# cslr_psc_001 register map
Vendor: Texas Instruments
Peripheral module from a debugger description file.
Registers are 32-bit, read-only, reset values left out (the file's numbers can be read two ways) unless marked. A register's access mark holds for its fields unless they carry their own. Offsets are as the file gives them; lines under a group give offsets from that group; [hi:lo] are bit positions; {n}, {i} and the like mark numbered series; 'fields as' and 'values as' point back to an identical list; <NAME> marks a mode.

## PSC — Power and Sleep Controller (PSC)
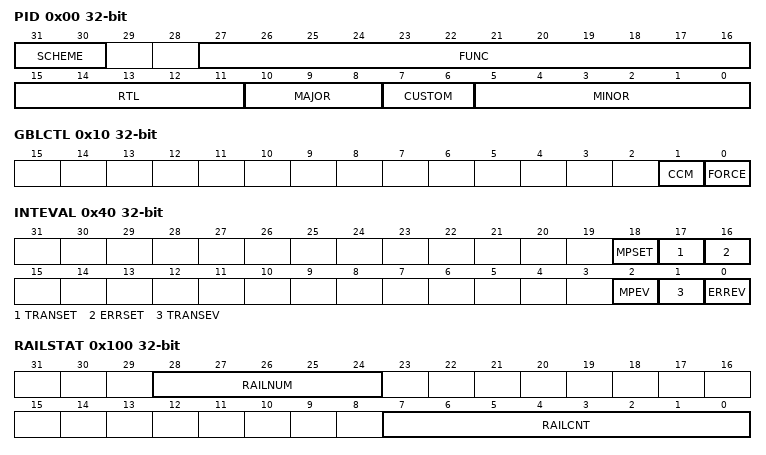
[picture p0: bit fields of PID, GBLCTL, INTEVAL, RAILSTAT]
0x00 PID — Peripheral Revision and Class Information
  [31:30] SCHEME — Used to distinguish between old scheme and current. Spare bit to encode future schemes
  [27:16] FUNC — Indicating a software compatible module family. If there is no level of software compatibility a new ID should be assigned.
  [15:11] RTL — RTL Version. (R as described in PDR 9.3.2) Must be easily ECO'able or controlled during fabrication. Ideally through a top level metal mask or efuse. Start with 0 for PSC1.0, 1 for PSC2.0
  [10:8] MAJOR — Major Revision.
  [7:6] CUSTOM — Indicates a Special Version for a particular device. Consequence of use may avoid use of standard CSL/Drivers. 0 if non-custom
  [5:0] MINOR — Minor Revision Must be easily ECO'able or controlled during fabrication. Ideally through a top level metal mask or efuse. Start with 0.
0x10 GBLCTL access per field — Global Control Register
  [1] CCM rw — PSC MMR controlled by Chip Config Module (CCM) only 0: Software is allowed to control PSC 1: PSC is controlled by CCM
  [0] FORCE rw — Force bit. For PSC 2.0, this bit is considered only if all of the conditions are true: -GBLCTL.CCM = 0 -Software manual control method is used 0: No force 1: Force
0x14 GBLSTAT — Global Status Register
  [0] GBLTRANS — PSC Global Transition Status 0: No Global Transition in progress 1: Global Transition in progress. PSC hardware is in the process of putting all power domains to the desired next states, and all modules to the desired next states
0x20 ERRPR0 — Error Pending 0 (mod 0 - 31) Register
  [31:0] M_32 — Records pending error conditions for modules 0-31. Each bit n respresents a module. For each bit n, 0: Module n does not have error condition 1: Module n has error condition
0x24 ERRPR1 — Error Pending 1 (mod 32 - 63) Register
  [31:0] M_32 — Records pending error conditions for modules 32-63. Each bit n respresents a module. For each bit n, 0: Module n does not have error condition 1: Module n has error condition
0x30 ERRCR0 wo — Error Clear 0 (mod 0-31) Register
  [31:0] M_32 — Clears error bit set in corresponding ERRPR register bit field. This pertains to modules 0-31. For each bit n, 0: Write of 0 has no effect 1: Write of 1 to bit n causes ERRPR bit n to be cleared, and the corresponding module's MDSTAT fields to be cleared - STERR, WKRSLP, ACSLP, MSTID.
0x34 ERRCR1 wo — Error Clear 1 (mod 32-63) Register
  [31:0] M_32 — Clears error bit set in corresponding ERRPR register bit field. This pertains to modules 32-63. For each bit n, 0: Write of 0 has no effect 1: Write of 1 to bit n causes ERRPR bit n to be cleared, and the corresponding module's MDSTAT fields to be cleared - STERR, WKRSLP, ACSLP, MSTID.
0x40 INTEVAL access per field — Interrupt Evaluation Register
  [18] MPSET wo — Memory Protection Interrupt Set (not documented to users) 0: Write of 0 has no effect 1: Write of 1 causes the PSC_MPINT to be pulsed
  [17] TRANSET wo — State Transition Interrupt Set (not documented to users) 0: Write of 0 has no effect 1: Write of 1 causes the PSC_TRANSINT to be pulsed
  [16] ERRSET wo — Error Interrupt Set (not documented to users) 0: Write of 0 has no effect 1: Write of 1 causes the PSC_ERRINT to be pulsed
  [2] MPEV wo — Re-evaluate Memory Protection Interrupt 0: Write of 0 has no effect 1: Write of 1 re-evaluates memory protection interrupt PSC_MPINT. Write of 1 causes interrupt logic to re-evaluate all pending Memory Protection error conditions and re-pulse the PSC_MPINT if any memory protection error conditions are pending
  [1] TRANSEV wo — Re-evaluate State Transition Interrupt 0: Write of 0 has no effect 1: Write of 1 re-evaluates state transition interrupt PSC_TRANSINT. Write of 1 causes interrupt logic to re-evaluate all pending MTSTAT conditions and re-pulse the PSC_TRANSINT if any MTSTAT bits are still set.
  [0] ERREV wo — Re-evaluate Error Interrupt 0: Write of 0 has no effect 1: Write of 1 re-evaluates error interrupt PSC_ERRINT. Write of 1 causes interrupt logic to re-evaluate all pending error interrupts and re-pulse the error interrupt signal if any error interrupt conditions are pending
0x100 RAILSTAT — Power Rail Status Register
  [28:24] RAILNUM — Indicates Current Rail Requestor being processed by GPSC. Defaults to 0 indicating Always ON domain that has no rail request/grant associated with it. The 5 bit field allows up to 32 requestors.
  [7:0] RAILCNT — Indicates the current rail counter value. This is a dynamic field and reading this will not reflect real-time value.
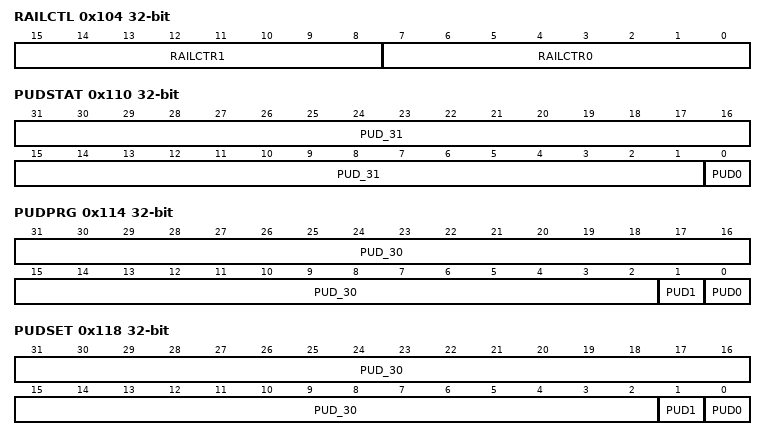
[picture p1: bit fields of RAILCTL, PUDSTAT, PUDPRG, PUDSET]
0x104 RAILCTL access per field — Power Rail Counter Control Register
  [15:8] RAILCTR1 rw — Rail Counter Value 1
  [7:0] RAILCTR0 rw — Rail Counter Value 0
0x108 RAILSEL rw — Power Rail Counter Select Register
  [31:0] P_32 — Rail Counter Select for Power Domain n 0: Use RAILCTL.RailCtr0 count value to bring up power domain n 1: Use RAILCTL.RailCtr1 count value to bring up power domain n
0x110 PUDSTAT — Power Up Domain Status Register
  [31:1] PUD_31 — Indicates Power ON for each power domain after the respective PUD bit is turned ON. This bit should be polled before turning OFF the isolation cells.
  [0] PUD0 — This bit indicates that the power is ON and stable for the Always ON domain. 0: Power not ON (may be in progress) 1: Power for domain is ON PUD0 belongs to the Always ON domain and therefore it defaults to ON (1)
0x114 PUDPRG — Power Up Domain Programmed Register
  [31:2] PUD_30 — Power Up Domain n , where n ranges 31 down-to 2. 0: Power domain n turns OFF 1: Power domain n turns ON
  [1] PUD1 — Power Up Domain 1 0: Power Domain 1 turns OFF 1: Power Domain 1 turns ON
  [0] PUD0 — Always ON Power Domain control bit. This bit is tied off to 1. Modules that need to be powered on along with the device belong in this power domain.
0x118 PUDSET access per field — Power Up Domain Set Register
  [31:2] PUD_30 wo — Power Up Domains n, where n ranges 31 down-to 2. 0: Writes of 0 have no effect 1: Writes of 1 asserts PUDPRG.PUD[n] to initiate power on for domain n
  [1] PUD1 wo — Power Up Domain 1 0: Writes of 0 have no effect 1: Writes of 1 asserts PUDPRG.PUD1 to initiate power on for domain 1
  [0] PUD0 ro — Set PUDPRG bit 0. Note that Power Domain 0 is the Always On power domain, which is always on. Therefore this bit is special and it is not writeable.
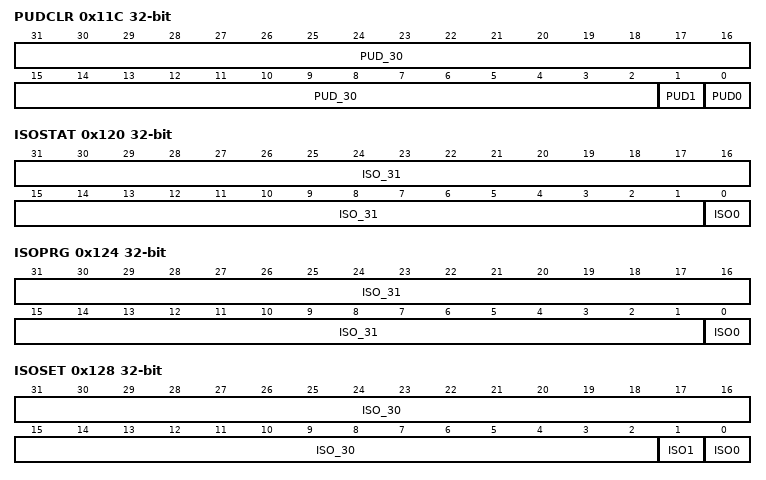
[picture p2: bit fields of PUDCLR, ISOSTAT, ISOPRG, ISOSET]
0x11C PUDCLR access per field — Power Up Domain Clear Register
  [31:2] PUD_30 wo — Power Down Domains n, where n ranges 31 down-to 2. 0: Writes of 0 have no effect 1: Writes of 1 clears PUDPRG.PUD[n] to turn off power for domain n
  [1] PUD1 wo — Power Down Domain 1 0: Writes of 0 have no effect 1: Writes of 1 clears PUDPRG.PUD1 to turn off power for domain 1
  [0] PUD0 ro — Clear PUDPRG bit 0. Note that Power Domain 0 is the Always On power domain, which is always on. Therefore this bit is special and it is not writeable to change the domain state.
0x120 ISOSTAT — Isolation Status Register
  [31:1] ISO_31 — Isolation cell status for power domains 31 down to 1: 0: Power domain is not isolated. 1: Power domain is isolated.
  [0] ISO0 — Always ON Power Domain's Isolation cell status bit. This bit indicates that the domain is not isolated (0).
0x124 ISOPRG — Isolation Cell Programmed Register
  [31:1] ISO_31 — Isolation cell control for power domains 31 down to 1: 0: Isolation cell is OFF. Power domain is not isolated 1: Isolation cell is ON. Power domain is isolated The actual ON or OFF stable state is read from the isolation Cell Status register.
  [0] ISO0 — Always ON Power Domain's Isolation cell control bit. This bit is tied to 0
0x128 ISOSET access per field — Isolation Cell Set Register
  [31:2] ISO_30 wo — Turn on the isolations cells for Power domains 31 down to 2: 0: Writes of 0 have no effect 1: Writes of 1 asserts ISOPRG.ISO[n] to tun on iso. cells for domain n
  [1] ISO1 wo — Turn on the isolations cells for Power domain 1 0: Writes of 0 have no effect 1: Writes of 1 asserts ISOPRG.ISO1 to tun on iso. cells for domain 1
  [0] ISO0 ro — Set ISOPRG bit 0. Note that Power Domain 0 is the Always ON power domain and therefore the isolation cells are always off (0). Therefore this bit is special and it is not writeable.
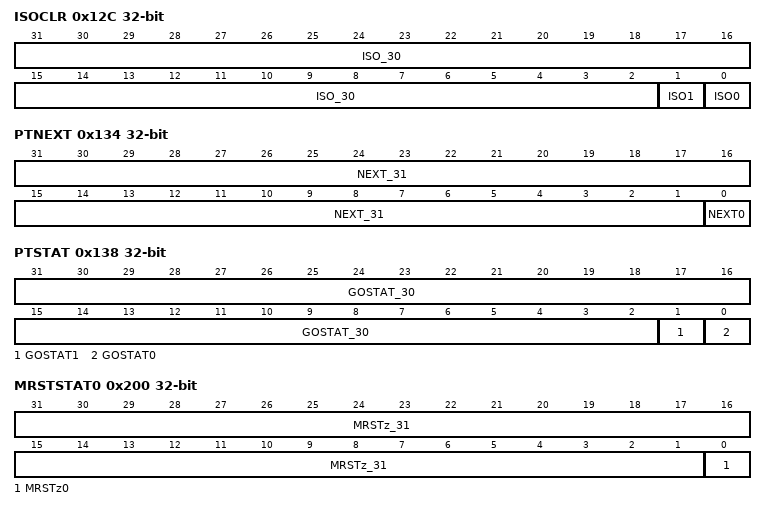
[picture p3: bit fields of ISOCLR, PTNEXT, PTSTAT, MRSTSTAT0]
0x12C ISOCLR access per field — Isolation Cell Clear Register
  [31:2] ISO_30 wo — Clear ISO[n] bit to turn off iso. Cells for Power Domain n , where n ranges from 31 down-to 2. 0: Writes of 0 have no effect 1: Writes of 1 clears ISO[n] to turn off iso cells for domain n
  [1] ISO1 wo — Clear ISO1 bit to turn off iso. Cells for Power Domain 1. 0: Writes of 0 have no effect 1: Writes of 1 clears ISO1 to turn off iso cells for domain 1
  [0] ISO0 ro — Clear ISO0. Note that Power Domain 0 is the Always ON power domain and therefore the isolations cells are always off. Therefore this bit is special and it is not writeable to change the domain state.
0x130 PTCMD rw — Power Domain Transition Command Register
  [31:0] GO_32 — PSC 1.0 definition: Power Domain n Evaluation 0: Writes of 0 has no effect 1: Writes of 1 cause the State Transition Interrupt Generation Block to evaluate the new PTNEXT and MDCTL.NEXT states as the Application desired states. PSC 2.0 definition: Power Domain n GO Transition 0: Writes of 0 have no effect 1: Writes of 1 cause PSC hardware to evaluate PTNEXT and MDCTL.NEXT (for this domain).
0x134 PTNEXT — Power Domain Transition Next State Register
  [31:1] NEXT_31 — Power Domain n Next State 0: OFF(PUD = 0, ISO = 1) 1: ON (PUD = 1, ISO = 0)
  [0] NEXT0 — Power Domain 0 Next State Since power domain 0 is reserved for the Always ON domain, this bit is always 1 to indicate that Power Domain 0's next state is ON.
0x138 PTSTAT — Power Domain Transition Status Register
  [31:2] GOSTAT_30 — Power Domain n Transition Command Status, where n ranges from 31 down to 2 0: No transitions in progress in Power Domain 0 1: Power Domain 0 Transition in progress - either the power domain is transitioning, or modules on this domain are transitioning.
  [1] GOSTAT1 — Power Domain 1 Transition Command Status 0: No transitions in progress in Power Domain 0 1: Power Domain 0 Transition in progress - either the power domain is transitioning, or modules on this domain are transitioning.
  [0] GOSTAT0 — Power Domain 0 Transition Command Status Power domain 0 is reserved for the Always ON domain, this bit is always 0.
0x200 MRSTSTAT0 — Module Reset Status 0 (mod 0 - 31) Register
  [31:1] MRSTz_31 — Shows Module 1 to Module 31's reset status
  [0] MRSTz0 — 0: Module reset is asserted low. 1: Module reset is de-asserted high.
0x204 MRSTSTAT1 — Module Reset Status 1 (mod 32-63) Register
  [31:0] MRSTz_32 — Shows Module 32 to Module 63's reset status
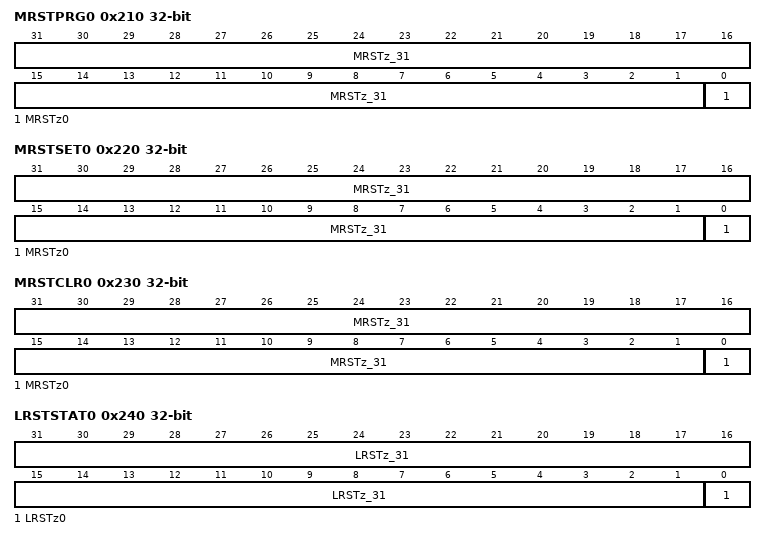
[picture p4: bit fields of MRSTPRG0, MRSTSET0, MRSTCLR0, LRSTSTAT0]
0x210 MRSTPRG0 — Module Reset Programmed 0 (mod 0 - 31) Register
  [31:1] MRSTz_31 — Controls Module 1 to Module 31's reset
  [0] MRSTz0 — 0: Module reset is asserted low. 1: Module reset is de-asserted high.
0x214 MRSTPRG1 — Module Reset Programmed 1 (mod 32 - 63) Register
  [31:0] MRSTz_32 — Controls Module 32 to Module 63's reset
0x220 MRSTSET0 wo — Module Reset Set 0 (mod 0 - 31) Register
  [31:1] MRSTz_31 — For Modules 31 down to 1, 0: Writes of 0 have no effect 1: Writes of 1 set MRSTz[n] to de-assert reset to that module
  [0] MRSTz0 — Set to de-assert module reset 0: Writes of 0 have no effect 1: Writes of 1 set MRSTz0 to de-assert reset to module 0
0x224 MRSTSET1 wo — Module Reset Set 1 (mod 32 - 63) Register
  [31:0] MRSTz_32 — For Modules 63 down to 32, 0: Writes of 0 have no effect 1: Writes of 1 set MRSTz[n] to de-assert reset to that module
0x230 MRSTCLR0 wo — Module Reset Clear 0 (mod 0 - 31) Register
  [31:1] MRSTz_31 — For Modules 31 down to 1, 0: Writes of 0 have no effect 1: Writes of 1 clear MRSTz[n] to assert reset to that module
  [0] MRSTz0 — Clear to assert module reset 0: Writes of 0 have no effect 1: Writes of 1 clear MRSTz0 to assert reset to module 0
0x234 MRSTCLR1 wo — Module Reset Clear 1 (mod 32 - 63) Register
  [31:0] MRSTz_32 — For Modules 63 down to 32, 0: Writes of 0 have no effect 1: Writes of 1 clear MRSTz[n] to assert reset to that module
0x240 LRSTSTAT0 — Module Local Reset Status 0 (mod 0 - 31) Register
  [31:1] LRSTz_31 — Shows Module 1 to Module 31's local reset status
  [0] LRSTz0 — 0: Module local reset is asserted. 1: Module local reset is de-asserted.
0x244 LRSTSTAT1 — Module Local Reset Status 1 (mod 32-63) Register
  [31:0] MRSTz_32 — Shows Module 32 to Module 63's local reset status
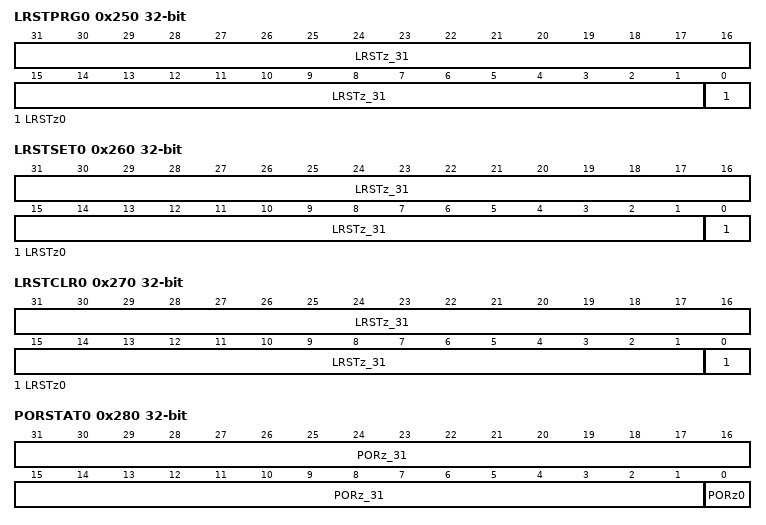
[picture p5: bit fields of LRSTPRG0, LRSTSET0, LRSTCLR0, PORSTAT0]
0x250 LRSTPRG0 — Module Local Reset Programmed 0 (mod 0 - 31) Register
  [31:1] LRSTz_31 — Controls Module 1 to Module 31's local reset
  [0] LRSTz0 — 0: Module local reset is asserted. 1: Module local reset is de-asserted.
0x254 LRSTPRG1 — Module Local Reset Programmed 1 (mod 32 - 63) Register
  [31:0] LRSTz_32 — Controls Module 32 to Module 63's local reset
0x260 LRSTSET0 wo — Module Local Reset Set 0 (mod 0 - 31) Register
  [31:1] LRSTz_31 — For Modules 31 down to 1, 0: Writes of 0 have no effect 1: Writes of 1 set LRSTz[n] to de-assert local reset to that module
  [0] LRSTz0 — Set to de-assert module local reset 0: Writes of 0 have no effect 1: Writes of 1 set LRSTz0 to de-assert local reset to module 0
0x264 LRSTSET1 wo — Module Local Reset Set 1 (mod 32 - 63) Register
  [31:0] LRSTz_32 — For Modules 63 down to 32, 0: Writes of 0 have no effect 1: Writes of 1 set LRSTz[n] to de-assert local reset to that module
0x270 LRSTCLR0 wo — Module Local Reset Clear 0 (mod 0 - 31) Register
  [31:1] LRSTz_31 — For Modules 31 down to 1, 0: Writes of 0 have no effect 1: Writes of 1 clear LRSTz[n] to assert local reset to that module
  [0] LRSTz0 — Clear to assert module local reset 0: Writes of 0 have no effect 1: Writes of 1 clear LRSTz0 to assert local reset to module 0
0x274 LRSTCLR1 wo — Module Local Reset Clear 1 (mod 32 - 63) Register
  [31:0] LRSTz_32 — For Modules 63 down to 32, 0: Writes of 0 have no effect 1: Writes of 1 clear LRSTz[n] to assert local reset to that module
0x280 PORSTAT0 — Module Power On Reset Status 0 (mod 0 - 31) Register
  [31:1] PORz_31 — Shows Module 1 to Module 31's PORz reset status
  [0] PORz0 — 0: Module PORz reset is asserted. 1: Module PORz reset is de-asserted.
0x284 PORSTAT1 — Module Power On Reset Status 1 (mod 32-63) Register
  [31:0] PORz_32 — Shows Module 32 to Module 63's PORz reset status
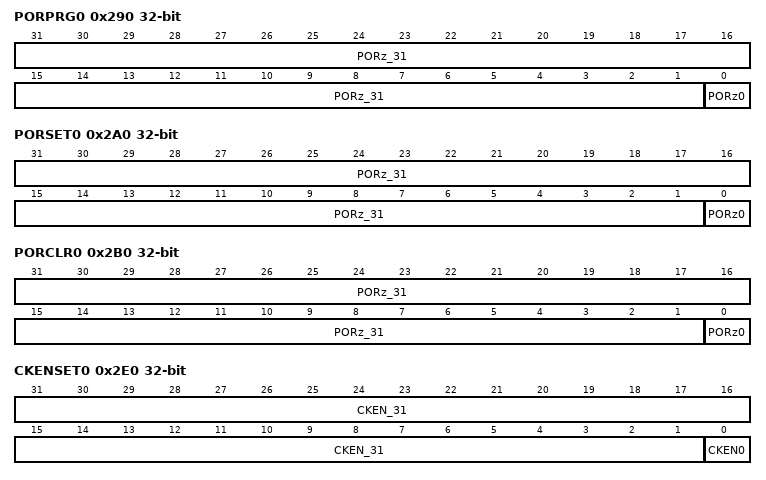
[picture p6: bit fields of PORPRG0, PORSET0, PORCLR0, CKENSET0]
0x290 PORPRG0 — Module Power On Reset Programmed 0 (mod 0 - 31) Register
  [31:1] PORz_31 — Controls Module 1 to Module 31's PORz reset
  [0] PORz0 — 0: Module PORz reset is asserted. 1: Module PORz reset is de-asserted.
0x294 PORPRG1 — Module Power On Reset Programmed 1 (mod 32 - 63) Register
  [31:0] PORz_32 — Controls Module 32 to Module 63's PORz reset
0x2A0 PORSET0 wo — Module Power On Reset Set 0 (mod 0 - 31) Register
  [31:1] PORz_31 — For Modules 31 down to 1, 0: Writes of 0 have no effect 1: Writes of 1 set PORz[n] to de-assert PORz reset to that module
  [0] PORz0 — Set to de-assert module PORz reset 0: Writes of 0 have no effect 1: Writes of 1 set PORz0 to de-assert PORz reset to module 0
0x2A4 PORSET1 wo — Module Power On Reset Set 1 (mod 32 - 63) Register
  [31:0] PORz_32 — For Modules 63 down to 32, 0: Writes of 0 have no effect 1: Writes of 1 set PORz[n] to de-assert PORz reset to that module
0x2B0 PORCLR0 wo — Module Power On Reset Clear 0 (mod 0 - 31) Register
  [31:1] PORz_31 — For Modules 31 down to 1, 0: Writes of 0 have no effect 1: Writes of 1 clear PORz[n] to assert PORz reset to that module
  [0] PORz0 — Clear to assert module PORz reset 0: Writes of 0 have no effect 1: Writes of 1 clear PORz0 to assert PORz reset to module 0
0x2B4 PORCLR1 wo — Module Power On Reset Clear 1 (mod 32 - 63) Register
  [31:0] PORz_32 — For Modules 63 down to 32, 0: Writes of 0 have no effect 1: Writes of 1 clear PORz[n] to assert PORz reset to that module
0x2C0 CKENSTAT0 — Module Clock Enable Status 0 (mod 0 - 31) Register
  [31:0] CKEN_32 — 0: Module clock is gated 1: Module clock is running. Does not have a direct relation to enabled state of the module.
0x2C4 CKENSTAT1 — Module Clock Enable Status 1 (mod 32-63) Register
  fields as CKENSTAT0
0x2D0 CKENPRG0 — Module Clock Enable Programmed 0 (mod 0 - 31) Register
  [31:0] CKEN_32 — 0:Gate Module Clock. 1: Ungate Module Clock.
0x2D4 CKENPRG1 — Module Clock Enable Programmed 1 (mod 32 - 63) Register
  [31:0] CKEN_32 — 0:Gate Module Clock. 1: Ungate Module Clock.
0x2E0 CKENSET0 wo — Module Clock Enable Set 0 (mod 0 - 31) Register
  [31:1] CKEN_31 — For Modules 31 down to 1, 0: Writes of 0 have no effect 1: Writes of 1 set CKEN[n] to turn on clock to that module
  [0] CKEN0 — Set CKEN0 = 1 to turn on module clock 0: Writes of 0 have no effect 1: Writes of 1 set CKEN0 to turn on clock to module 0
0x2E4 CKENSET1 wo — Module Clock Enable Set 1 (mod 32 - 63) Register
  [31:0] CKEN_32 — For Modules 63 down to 32, 0: Writes of 0 have no effect 1: Writes of 1 set CKEN[n] to turn on clock to that module
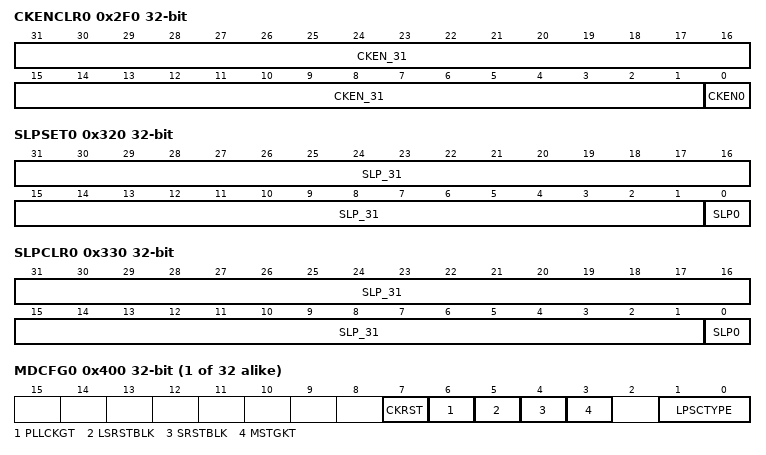
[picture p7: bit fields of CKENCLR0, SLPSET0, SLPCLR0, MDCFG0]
0x2F0 CKENCLR0 wo — Module Clock Enable Clear 0 (mod 0 - 31) Register
  [31:1] CKEN_31 — For Modules 31 down to 1, 0: Writes of 0 have no effect 1: Writes of 1 clear CKEN[n] to gate clock to that module
  [0] CKEN0 — Clear CKEN0 = 0 to gate module clock 0: Writes of 0 have no effect 1: Writes of 1 clear CKEN0 to gate clock to module 0
0x2F4 CKENCLR1 wo — Module Clock Enable Clear 1 (mod 32 - 63) Register
  [31:0] CKEN_32 — For Modules 63 down to 32, 0: Writes of 0 have no effect 1: Writes of 1 clear CKEN[n] to gate clock to that module
0x300 SLPSTAT0 — Module Sleep Status 0 (mod 0 - 31) Register
  [31:0] SLP0_32 — 0: Module is not in sleep state or any transitional states related to Sleep mode 1: Module is in Sleep state or any transitional states related to Sleep mode
0x304 SLPSTAT1 — Module Sleep Status 1 (mod 32-63) Register
  [31:0] SLP1_32 — 0: Module is not in sleep state or any transitional states related to Sleep mode 1: Module is in Sleep state or any transitional states related to Sleep mode
0x310 SLPPRG0 — Module Sleep Programmed 0 (mod 0 - 31) Register
  [31:0] SLP0_32 — 0: Do not put module in sleep state or any transitional states related to sleep mode 1: Put module in sleep state or transitional states related to sleep mode
0x314 SLPPRG1 — Module Sleep Programmed 1 (mod 32 - 63) Register
  [31:0] SLP1_32 — 0: Do not put module in sleep state or any transitional states related to sleep mode 1: Put module in sleep state or transitional states related to sleep mode
0x320 SLPSET0 wo — Module Sleep Set 0 (mod 0 - 31) Register
  [31:1] SLP_31 — For Modules 31 down to 1, 0: Writes of 0 have no effect 1: Writes of 1 set SLP[n]
  [0] SLP0 — Set SLP0 = 1 0: Writes of 0 have no effect 1: Writes of 1 set SLP0
0x324 SLPSET1 wo — Module Sleep Set 1 (mod 32 - 63) Register
  [31:0] SLP_32 — For Modules 63 down to 32, 0: Writes of 0 have no effect 1: Writes of 1 set SLP[n]
0x330 SLPCLR0 wo — Module Sleep Clear 0 (mod 0 - 31) Register
  [31:1] SLP_31 — For Modules 31 down to 1, 0: Writes of 0 have no effect 1: Writes of 1 clears SLP[n]
  [0] SLP0 — Clear SLP0 = 0 0: Writes of 0 have no effect 1: Writes of 1 clear SLP0
0x334 SLPCLR1 wo — Module Sleep Clear 1 (mod 32 - 63) Register
  [31:0] SLP_32 — For Modules 63 down to 32, 0: Writes of 0 have no effect 1: Writes of 1 clear SLP[n]
0x340 TWKSTAT0 — Module Temporary Wakeup Status 0 (mod 0 - 31) Register
  [31:0] TWK0_32 — This register holds the temporary wakeup status of modules 0 - 31 0: Module is not in TWK state or any transitional states related to temporary wakeup 1: Module is in TWK state or any transitional states related to temporary wakeup
0x344 TWKSTAT1 — Module Temporary Wakeup Status 1 (mod 32 - 63) Register
  [31:0] TWK1_32 — This register holds the temporary wakeup status of modules 32-63 0: Module is not in TWK state or any transitional states related to temporary wakeup 1: Module is in TWK state or any transitional states related to temporary wakeup
0x350 TWKPRG0 — Module Temporary Wakeup Programmed 0 (mod 0 - 31) Register
  [31:0] TWK0_32 — This register holds the temporary wakeup status of modules 0 - 31 0: Do not put module in TWK state or any transitional states related to temporary wakeup 1: Put module in TWK state or any transitional states related to temporary wakeup
0x354 TWKPRG1 — Module Temporary Wakeup Programmed 1 (mod 32 - 63) Register
  [31:0] TWK1_32 — This register holds the temporary wakeup status of modules 32-63 0: Do not put module in TWK state or any transitional states related to temporary wakeup 1: Put module in TWK state or any transitional states related to temporary wakeup
0x360 MTSTAT0 — Module Transition Status 0 (mod 0 - 31) Register
  [31:0] M_32 — PSC 1.0 Definition: Module n State Transition 0: No state transition required for this module 1: State transition required for this module PSC2.0 Definition: Module n State Transition 0: Module n is not going through state transition 1: Module n state transition is in progress Note that n ranges from 0 to 31 in this case
0x364 MTSTAT1 — Module Transition Status 1 (mod 32 - 63) Register
  [31:0] M_32 — PSC 1.0 Definition: Module n State Transition 0: No state transition required for this module 1: State transition required for this module PSC2.0 Definition: Module n State Transition 0: Module n is not going through state transition 1: Module n state transition is in progress Note that n ranges from 32 to 63 in this case
0x370 MTCLR0 rw — Module Transition Clear 0 (mod 0 - 31) Register
  [31:0] M_32 — Module n Transition Status Clear, where n ranges from 0 to 31 Writes of 1 clear the corresponding bit in MTSTAT. Writes of 0 have no effect. This register is used for Software Manual Control method- so that whenever software is done servicing the desired state transition, it can use this register to clear the corresponding status.
0x374 MTCLR1 rw — Module Transition Clear 1 (mod 32 - 63) Register
  [31:0] M_32 — Module n Transition Status Clear, where n ranges from 32 to 63 Writes of 1 clear the corresponding bit in MTSTAT. Writes of 0 have no effect. This register is used for Software Manual Control method- so that whenever software is done servicing the desired state transition, it can use this register to clear the corresponding status.
0x380 ICEINHB0 — IcePick Inhibit Off 0 (mod 0 - 31) Register
  [31:0] M_32 — IcePick Inhibit Off Request for Module n, where n ranges from 0 to 31 0: No IcePick Inhibit Off Request for Module n 1: IcePick Inhibit Off Request for Module n is detected
0x384 ICEINHB1 — IcePick Inhibit Off 1 (mod 32 - 63) Register
  [31:0] M_32 — IcePick Inhibit Off Request for Module n, where n ranges from 32 to 63 0: No IcePick Inhibit Off Request for Module n 1: IcePick Inhibit Off Request for Module n is detected
0x390 ICEFRC0 — IcePick Force On 0 (mod 0 - 31) Register
  [31:0] M_32 — IcePick Force On Request for Module n, where n ranges from 0 to 31 0: No IcePick Force On Request for Module n 1: IcePick Force On Request for Module n is detected
0x394 ICEFRC1 — IcePick Force On 1 (mod 32 - 63) Register
  [31:0] M_32 — IcePick Force On Request for Module n, where n ranges from 32 to 63 0: No IcePick Force On Request for Module n 1: IcePick Force On Request for Module n is detected
{0x400+4i} MDCFG{i} (i=0..31) — Module Configuration {i} Register
  [7] CKRST — Modclk during hard_rst_src_assert. Shows the tieoff d_mod[x]_hard_rst_src_assert. 0: LPSC does not give modclk when hard_rst_src_assert_pi_n = 0 (asserted). LPSC only gives modclk after this reset is de-asserted 1: LPSC gives modclk even when hard_rst_src_assert_pi_n = 0 (assert)
  [6] PLLCKGT — PLL Clock Gate. Shows the tieoff d_mod[x]_pll_clk_gate 0: LPSC gates modclk directly 1: LPSC does not gate modclk directly. LPSC instructs the PLLCTRL to gate modclk
  [5] LSRSTBLK — LRST Soft Reset Block. Shows the tieoff d_mod[x]_lrst_soft_rst_block value. 0: Soft resets are not blocked to LRST 1: Soft resets are blocked to LRST
  [4] SRSTBLK — Soft Reset Block. Shows the tieoff d_mod[x]_soft_rst_block value. 0: Soft resets are not blocked. Any grstz from PLLCTRL will be propagated to the module 1: Soft resets are blocked. LPSC only passes hard resets to the module
  [3] MSTGKT — Master Gasket support. Reflects the RTL parameter MSTGKT 0: Master Gasket not supported by LPSC 1: Master Gasket supported by LPSC
  [1:0] LPSCTYPE — LPSC Type. Reflects the RTL parameter LPSCTYPE 00: Single-Port LPSC (1PORT) 01: Dual-Clock LPSC (2CLK) 10: Dual-Port LPSC (2PORT) 11: Reserved
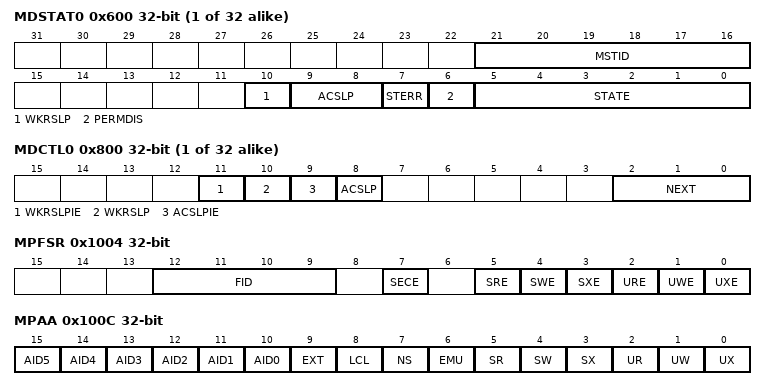
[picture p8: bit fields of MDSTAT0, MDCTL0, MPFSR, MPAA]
{0x600+4i} MDSTAT{i} (i=0..31) — Module Status {i} Register
  [21:16] MSTID — Master ID. If ACSLP occurs, this field records the master ID of the master that caused the access. This bit is cleared when the corresponding ERRCR bit is written with a 1.
  [10] WKRSLP — Wakeup Request to Module in Sleep Detected. Wakeup_pi is detected for this module when it is in sleep. If MDCTL.WKRSLPIE = 1, the setting of this field can cause ERRPR for this module to be set. 0: Condition did not occur 1: wakeup_pi = 1 when module is in sleep.
  [9:8] ACSLP — Non-emulation access to Module in Sleep occurred. 00: Condition did not occur 01: Access to module in sleep occurred. PSC transitioned the module from Sleep state to Temp Wake state then back to Sleep state 10: Access to module in sleep occured. PSC transitioned the module from Sleep state to Enable state 11: Reserved
  [7] STERR — State Transition Error 0: Error did not occur 1: Error occured
  [6] PERMDIS — Permanently Disable 0: Do not permanently disable module 1: Permanently disable module
  [5:0] STATE — These bits indiacte the current module state 010000: Power Domain Off 110000: Iso-PwrCtrl 111000: En-IsoCtrl 101000: SyncReset 100000: SwRstDisable 100100: Disable 101100: Enable 101110: SlpTrans 100110: Sleep 100111: TwkTrans 101111: Twk Others: Reserved
{0x800+4i} MDCTL{i} access per field (i=0..31) — Module Control {i} Register
  [11] WKRSLPIE rw — Wakeup Request to module in sleep Error Enable. 0: Wakeup request to module in sleep is not considered an error condition 1: Wakeup request to module in sleep is considered an error
  [10] WKRSLP rw — Wakeup Request to module in Sleep will cause this action. 0: PSC transitions module from Sleep state to TWK state, once access completes (vbus_req = 0) put module back in Sleep state 1: PSC transitions module to ENABLE state
  [9] ACSLPIE rw — Non-emulation Access to module in sleep Error enable 0: Non-emulation access to module in sleep is not considered an error condition 1: Non-emulation access to module in sleep is considered an error
  [8] ACSLP rw — Non-emulation Access to module in Sleep will cause this action 0: PSC transitions module from Sleep state to TWk state, once access completes put module back in Sleep state 1: PSC transitions module to ENABLE state
  [2:0] NEXT rw — Module Next State 000: SwRstDisable 001: Disable 010: SyncReset 011: Enable 100: Reserved/Invalid 101: Sleep 110: Reserved/Invalid 111: Reserved/Invalid
0x1000 MPFAR — Memory Protection Fault Address Register
  [31:0] FADDR — Memory Protection Fault Address Captures the faulting address when a memory protection vioaltion is detected. This register can only be cleared via MPFCR.MPFCLR
0x1004 MPFSR access per field — Memory Protection Fault Status Register
  [12:9] FID ro — Faulted ID FID contains valid info if any of the MP error bits (UXE, UWE, URE, SXE, SWE, SRE) are non-zero. The FID field contains the vbus PrivID for the specific request/requestor that resulted in a MP error.
  [7] SECE ro — Secure Access Error Hard-wired to 0 to show no secure access error - because PSC does not check for security.
  [5] SRE ro — Supervisor Read Error SRE = 0: No error detected SRE = 1: Supervisor level task attempted to read from a MP page without SR permissions
  [4] SWE ro — Supervisor Write Error SWE = 0: No error detected SWE = 1: Supervisor level task attempted to write to a MP page without SW permissions
  [3] SXE ro — Supervisor Execute Error. This bit is hard-wired to 0 to indicate no Supervisor Execute Error (because PSC does not check for VBUS data type vbus_dtype)
  [2] URE ro — User Read Error URE = 0: No Error detected URE = 1: User level task attempted to read from a MP page without UR permissions
  [1] UWE ro — User Write Error UWE = 0: No error detected UWE = 1: User level task attempted to write to a MP page without UW permissions
  [0] UXE ro — User Execute Error. This bit is hard-wired to 0 to indicate no User Execute Error (because PSC does not check for VBUS data type vbus_dtype)
0x1008 MPFCR access per field — Memory Protection Fault Command Register
  [0] MPFCLR wo — Fault Clear Write of 1 to this bit causes any error conditions stored in MPFAR and MPFSR registers to be cleared. Write of 0 has no effect
0x100C MPAA access per field — Memory Protection Page Attribute Register
  [n+10] AID{n} rw (n=0..5) — Allowed ID {n} AID{n} = 0: VBUS requests with PrivID == {n} are not allowed to this MMR region regardless of permission settings (UW, UR, SW, SR) AID{n} = 1: VBUS requests with PrivID == {n} are permitted if access type is allowed as defined by permission settings (UW, UR, SW, SR)
  [9] EXT rw — External Allowed ID EXT = 0: VBUS requests with PrivID >= 6 are not allowed to this MMR region regardless of permission settings (UW, UR, SW, SR) EXT = 1: VBUS requests with PrivID >= 6 are permitted if access type is allowed as defined by permission settings (UW, UR, SW, SR)
  [8] LCL ro — Local access permission (Not applicable) Local accesses are not applicable, therefore hard-code this value to 0
  [7] NS ro — Secure Access Permission (not applicable) Hard-wired to 1 to show page is not secure. Secure and non-secure code can both access this MMR region.
  [6] EMU ro — Emulation Security Permission (not applicable) Hard-wired to 1 to indicate emulation read/write to this page is permitted.
  [5] SR rw — Supervisor Read Permission UR = 0: Supervisor reads are not allowed to this MMR region UR = 1: Supervisor reads allowed to this MMR region
  [4] SW rw — Supervisor Write Permission UW = 0: Supervisor writes are not allowed to this MMR region UW = 1: Supervisor writes allowed to this MMR region
  [3] SX ro — Supervisor Execute Permission (not applicable) This bit is hard-wired to 0 to indicate no Supervisor Execute Permission (because PSC does not check for VBUS data type vbus_dtype)
  [2] UR rw — User Read Permission UR = 0: User reads not allowed to this MMR region UR = 1: User reads allowed to this MMR region
  [1] UW rw — User Write Permission UW = 0: User writesnot allowed to this MMR region UW = 1: User writes allowed to this MMR region
  [0] UX ro — User Execute Permission (not applicable) This bit is hard-wired to 0 to indicate no User Execute Permission (because PSC does not check for VBUS data type vbus_dtype)
